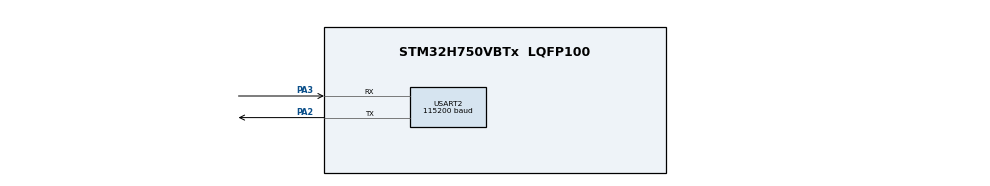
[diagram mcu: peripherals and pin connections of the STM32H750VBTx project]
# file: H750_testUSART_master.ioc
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CORTEX_M7.AccessPermission-Cortex_Memory_Protection_Unit_Region0_Settings=MPU_REGION_FULL_ACCESS
CORTEX_M7.BaseAddress-Cortex_Memory_Protection_Unit_Region0_Settings=0x24000000
CORTEX_M7.CPU_DCache=Enabled
CORTEX_M7.CPU_ICache=Enabled
CORTEX_M7.DisableExec-Cortex_Memory_Protection_Unit_Region0_Settings=MPU_INSTRUCTION_ACCESS_DISABLE
CORTEX_M7.Enable-Cortex_Memory_Protection_Unit_Region0_Settings=MPU_REGION_ENABLE
CORTEX_M7.IsBufferable-Cortex_Memory_Protection_Unit_Region0_Settings=MPU_ACCESS_BUFFERABLE
CORTEX_M7.IsShareable-Cortex_Memory_Protection_Unit_Region0_Settings=MPU_ACCESS_SHAREABLE
CORTEX_M7.MPU_Control=MPU_PRIVILEGED_DEFAULT
CORTEX_M7.Size-Cortex_Memory_Protection_Unit_Region0_Settings=MPU_REGION_SIZE_8KB
Dma.Request0=USART2_RX
Dma.Request1=USART2_TX
Dma.USART2_RX.0.Direction=DMA_PERIPH_TO_MEMORY
Dma.USART2_RX.0.EventEnable=DISABLE
Dma.USART2_RX.0.FIFOMode=DMA_FIFOMODE_DISABLE
Dma.USART2_RX.0.Instance=DMA1_Stream0
Dma.USART2_RX.0.MemDataAlignment=DMA_MDATAALIGN_BYTE
Dma.USART2_RX.0.MemInc=DMA_MINC_ENABLE
Dma.USART2_RX.0.Mode=DMA_CIRCULAR
Dma.USART2_RX.0.PeriphDataAlignment=DMA_PDATAALIGN_BYTE
Dma.USART2_RX.0.PeriphInc=DMA_PINC_DISABLE
Dma.USART2_RX.0.Polarity=HAL_DMAMUX_REQ_GEN_RISING
Dma.USART2_RX.0.Priority=DMA_PRIORITY_LOW
Dma.USART2_RX.0.RequestNumber=1
Dma.USART2_RX.0.SignalID=NONE
Dma.USART2_RX.0.SyncEnable=DISABLE
Dma.USART2_RX.0.SyncPolarity=HAL_DMAMUX_SYNC_NO_EVENT
Dma.USART2_RX.0.SyncRequestNumber=1
Dma.USART2_RX.0.SyncSignalID=NONE
Dma.USART2_TX.1.Direction=DMA_MEMORY_TO_PERIPH
Dma.USART2_TX.1.EventEnable=DISABLE
Dma.USART2_TX.1.FIFOMode=DMA_FIFOMODE_DISABLE
Dma.USART2_TX.1.Instance=DMA1_Stream1
Dma.USART2_TX.1.MemDataAlignment=DMA_MDATAALIGN_BYTE
Dma.USART2_TX.1.MemInc=DMA_MINC_ENABLE
Dma.USART2_TX.1.Mode=DMA_NORMAL
Dma.USART2_TX.1.PeriphDataAlignment=DMA_PDATAALIGN_BYTE
Dma.USART2_TX.1.PeriphInc=DMA_PINC_DISABLE
Dma.USART2_TX.1.Polarity=HAL_DMAMUX_REQ_GEN_RISING
Dma.USART2_TX.1.Priority=DMA_PRIORITY_LOW
Dma.USART2_TX.1.RequestNumber=1
Dma.USART2_TX.1.SignalID=NONE
Dma.USART2_TX.1.SyncEnable=DISABLE
Dma.USART2_TX.1.SyncPolarity=HAL_DMAMUX_SYNC_NO_EVENT
Dma.USART2_TX.1.SyncRequestNumber=1
Dma.USART2_TX.1.SyncSignalID=NONE
Mcu.Family=STM32H7
Mcu.Name=STM32H750VBTx
Mcu.Package=LQFP100
NVIC.DMA1_Stream0_IRQn=true\:0\:0\:false\:false\:true\:false\:true\:true
NVIC.DMA1_Stream1_IRQn=true\:0\:0\:false\:false\:true\:false\:true\:true
NVIC.PriorityGroup=NVIC_PRIORITYGROUP_4
NVIC.USART2_IRQn=true\:0\:0\:false\:false\:true\:true\:true\:true
PA13\ (JTMS/SWDIO).Mode=Serial_Wire
PA13\ (JTMS/SWDIO).Signal=DEBUG_JTMS-SWDIO
PA14\ (JTCK/SWCLK).Mode=Serial_Wire
PA14\ (JTCK/SWCLK).Signal=DEBUG_JTCK-SWCLK
PA2.GPIO_Speed=GPIO_SPEED_FREQ_LOW
PA2.Mode=Asynchronous
PA2.Signal=USART2_TX
PA3.GPIO_Speed=GPIO_SPEED_FREQ_LOW
PA3.Mode=Asynchronous
PA3.Signal=USART2_RX
PD7.GPIO_Speed=GPIO_SPEED_FREQ_LOW
PD7.Signal=USART2_CK
PH0-OSC_IN\ (PH0).Mode=HSE-External-Oscillator
PH0-OSC_IN\ (PH0).Signal=RCC_OSC_IN
PH1-OSC_OUT\ (PH1).Mode=HSE-External-Oscillator
PH1-OSC_OUT\ (PH1).Signal=RCC_OSC_OUT
ProjectManager.HeapSize=0x200
ProjectManager.StackSize=0x400
ProjectManager.TargetToolchain=STM32CubeIDE
RCC.ADCFreq_Value=48375000
RCC.APB1Freq_Value=120000000
RCC.APB2Freq_Value=120000000
RCC.APB3Freq_Value=120000000
RCC.APB4Freq_Value=120000000
RCC.CortexFreq_Value=480000000
RCC.D1PPRE=RCC_APB3_DIV2
RCC.D2PPRE1=RCC_APB1_DIV2
RCC.D2PPRE2=RCC_APB2_DIV2
RCC.D3PPRE=RCC_APB4_DIV2
RCC.DIVM1=4
RCC.DIVN1=160
RCC.EnbaleCSS=true
RCC.HCLKFreq_Value=240000000
RCC.HPRE=RCC_HCLK_DIV2
RCC.HSE_VALUE=24000000
RCC.PLLSourceVirtual=RCC_PLLSOURCE_HSE
RCC.SYSCLKFreq_VALUE=480000000
RCC.SYSCLKSource=RCC_SYSCLKSOURCE_PLLCLK
RCC.USBFreq_Value=480000000
USART2.BaudRate=115200
USART2.VirtualMode-Asynchronous=VM_ASYNC
board=custom

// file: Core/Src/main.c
/* USER CODE BEGIN Header */
/**
  ******************************************************************************
  * @file           : main.c
  * @brief          : Main program body
  ******************************************************************************
  * @attention
  *
  * Copyright (c) 2023 STMicroelectronics.
  * All rights reserved.
  *
  * This software is licensed under terms that can be found in the LICENSE file
  * in the root directory of this software component.
  * If no LICENSE file comes with this software, it is provided AS-IS.
  *
  ******************************************************************************
  */
/* USER CODE END Header */
#include "main.h"
#include "dma.h"
#include "usart.h"
#include "gpio.h"

/* USER CODE BEGIN PD */
#define IN_RAM_D1_DMA 	__attribute__ ((section(".ramd1dma"), used))
/* USER CODE END PD */

/* USER CODE BEGIN PV */
//=============================================================================
// DMA should be first
//
//
//=============================================================================
uint8_t tx_size = 7;
IN_RAM_D1_DMA uint8_t bufMasterTx[7];
uint8_t rx_size = 4;
IN_RAM_D1_DMA uint8_t bufMasterRx[4];
/* USER CODE END PV */

void SystemClock_Config(void);
static void MPU_Config(void);

int main(void)
{

  /* MPU Configuration--------------------------------------------------------*/
  MPU_Config();

  /* Enable I-Cache---------------------------------------------------------*/
  SCB_EnableICache();

  /* Enable D-Cache---------------------------------------------------------*/
  SCB_EnableDCache();

  /* MCU Configuration--------------------------------------------------------*/

  /* Reset of all peripherals, Initializes the Flash interface and the Systick. */
  HAL_Init();

  /* Configure the system clock */
  SystemClock_Config();

  /* Initialize all configured peripherals */
  MX_GPIO_Init();
  MX_DMA_Init();
  MX_USART2_UART_Init();

  /* USER CODE BEGIN 2 */
  for(int i = 0 ; i < tx_size; i++) {
  	bufMasterTx[i] = i+1;
  }
  for(int i = 0 ; i < rx_size; i++) {
  	bufMasterRx[i] = 0;
  }

  HAL_UART_Receive_DMA(&huart2, bufMasterRx, rx_size);
  /* USER CODE END 2 */

  /* Infinite loop */
  /* USER CODE BEGIN WHILE */
  while (1)
  {

	  HAL_Delay(500);
	  HAL_UART_Transmit_DMA(&huart2, bufMasterTx, tx_size);
    /* USER CODE END WHILE */

  }
}

void SystemClock_Config(void)
{
  RCC_OscInitTypeDef RCC_OscInitStruct = {0};
  RCC_ClkInitTypeDef RCC_ClkInitStruct = {0};

  /** Supply configuration update enable
  */
  HAL_PWREx_ConfigSupply(PWR_LDO_SUPPLY);

  /** Configure the main internal regulator output voltage
  */
  __HAL_PWR_VOLTAGESCALING_CONFIG(PWR_REGULATOR_VOLTAGE_SCALE1);

  while(!__HAL_PWR_GET_FLAG(PWR_FLAG_VOSRDY)) {}

  __HAL_RCC_SYSCFG_CLK_ENABLE();
  __HAL_PWR_VOLTAGESCALING_CONFIG(PWR_REGULATOR_VOLTAGE_SCALE0);

  while(!__HAL_PWR_GET_FLAG(PWR_FLAG_VOSRDY)) {}

  /** Initializes the RCC Oscillators according to the specified parameters
  * in the RCC_OscInitTypeDef structure.
  */
  RCC_OscInitStruct.OscillatorType = RCC_OSCILLATORTYPE_HSE;
  RCC_OscInitStruct.HSEState = RCC_HSE_ON;
  RCC_OscInitStruct.PLL.PLLState = RCC_PLL_ON;
  RCC_OscInitStruct.PLL.PLLSource = RCC_PLLSOURCE_HSE;
  RCC_OscInitStruct.PLL.PLLM = 4;
  RCC_OscInitStruct.PLL.PLLN = 160;
  RCC_OscInitStruct.PLL.PLLP = 2;
  RCC_OscInitStruct.PLL.PLLQ = 2;
  RCC_OscInitStruct.PLL.PLLR = 2;
  RCC_OscInitStruct.PLL.PLLRGE = RCC_PLL1VCIRANGE_2;
  RCC_OscInitStruct.PLL.PLLVCOSEL = RCC_PLL1VCOWIDE;
  RCC_OscInitStruct.PLL.PLLFRACN = 0;
  if (HAL_RCC_OscConfig(&RCC_OscInitStruct) != HAL_OK)
  {
    Error_Handler();
  }

  /** Initializes the CPU, AHB and APB buses clocks
  */
  RCC_ClkInitStruct.ClockType = RCC_CLOCKTYPE_HCLK|RCC_CLOCKTYPE_SYSCLK
                              |RCC_CLOCKTYPE_PCLK1|RCC_CLOCKTYPE_PCLK2
                              |RCC_CLOCKTYPE_D3PCLK1|RCC_CLOCKTYPE_D1PCLK1;
  RCC_ClkInitStruct.SYSCLKSource = RCC_SYSCLKSOURCE_PLLCLK;
  RCC_ClkInitStruct.SYSCLKDivider = RCC_SYSCLK_DIV1;
  RCC_ClkInitStruct.AHBCLKDivider = RCC_HCLK_DIV2;
  RCC_ClkInitStruct.APB3CLKDivider = RCC_APB3_DIV2;
  RCC_ClkInitStruct.APB1CLKDivider = RCC_APB1_DIV2;
  RCC_ClkInitStruct.APB2CLKDivider = RCC_APB2_DIV2;
  RCC_ClkInitStruct.APB4CLKDivider = RCC_APB4_DIV2;

  if (HAL_RCC_ClockConfig(&RCC_ClkInitStruct, FLASH_LATENCY_4) != HAL_OK)
  {
    Error_Handler();
  }

  /** Enables the Clock Security System
  */
  HAL_RCC_EnableCSS();
}

/* MPU Configuration */

void MPU_Config(void)
{
  MPU_Region_InitTypeDef MPU_InitStruct = {0};

  /* Disables the MPU */
  HAL_MPU_Disable();

  /** Initializes and configures the Region and the memory to be protected
  */
  MPU_InitStruct.Enable = MPU_REGION_ENABLE;
  MPU_InitStruct.Number = MPU_REGION_NUMBER0;
  MPU_InitStruct.BaseAddress = 0x24000000;
  MPU_InitStruct.Size = MPU_REGION_SIZE_8KB;
  MPU_InitStruct.SubRegionDisable = 0x0;
  MPU_InitStruct.TypeExtField = MPU_TEX_LEVEL0;
  MPU_InitStruct.AccessPermission = MPU_REGION_FULL_ACCESS;
  MPU_InitStruct.DisableExec = MPU_INSTRUCTION_ACCESS_DISABLE;
  MPU_InitStruct.IsShareable = MPU_ACCESS_SHAREABLE;
  MPU_InitStruct.IsCacheable = MPU_ACCESS_NOT_CACHEABLE;
  MPU_InitStruct.IsBufferable = MPU_ACCESS_BUFFERABLE;

  HAL_MPU_ConfigRegion(&MPU_InitStruct);
  /* Enables the MPU */
  HAL_MPU_Enable(MPU_PRIVILEGED_DEFAULT);

}

void Error_Handler(void)
{
  __disable_irq();
  while (1)
  {
  }
}
